VERSION "2027-draft-2026-10-22"

NS_ :

BS_:

BU_: Blackbody1 Blackbody2 Blackbody3 ChassisIMU StrainGauge1 StrainGauge2 StrainGauge3 StrainGauge4 StrainGauge5 StrainGauge6 SuspensionFL SuspensionFR SuspensionRear TelemetryLeader UprightFL UprightFR UprightRear
VAL_TABLE_ EnableDisable 1 "Enabled" 0 "Disabled" ;
VAL_TABLE_ OnOff 1 "On" 0 "Off" ;
VAL_TABLE_ FaultState 1 "Fault" 0 "OK" ;
VAL_TABLE_ WarningState 1 "Warning" 0 "NoWarning" ;
VAL_TABLE_ DeviceStatus 2 "Waiting" 1 "Fault" 0 "OK" ;
VAL_TABLE_ Permission 1 "Allowed" 0 "NotAllowed" ;
VAL_TABLE_ Connection 1 "Connected" 0 "Disconnected" ;
VAL_TABLE_ Pressed 1 "Pressed" 0 "NotPressed" ;
VAL_TABLE_ Validity 1 "Valid" 0 "Invalid" ;
VAL_TABLE_ Watchdog 1 "TimedOut" 0 "Alive" ;
VAL_TABLE_ NormalAdvanced 1 "Advanced" 0 "Normal" ;
VAL_TABLE_ MotorCommandSource 1 "External" 0 "VCU" ;
VAL_TABLE_ Gear 3 "Invalid" 2 "Reverse" 1 "Forward" 0 "Neutral" ;
VAL_TABLE_ BPSFaultSummary 5 "SMBFault" 4 "PrechargeFault" 3 "ContactorRelayFault" 2 "EmergencyStop" 1 "SetpointFault" 0 "OK" ;
VAL_TABLE_ VCUState 7 "VehicleNotReady" 6 "Disabled" 5 "CruiseControl" 4 "Regen" 3 "ReverseDrive" 2 "NeutralDrive" 1 "ForwardDrive" 0 "Init" ;
VAL_TABLE_ ChargeState 2 "Charging" 1 "Standby" 0 "Disabled" ;
VAL_TABLE_ EVSEState 5 "F_EVSEFault" 4 "E_Fault" 3 "D_VentilationRequired" 2 "C_ChargingReady" 1 "B_Connected" 0 "A_Disconnected" ;
VAL_TABLE_ GPSAntennaState 3 "Unknown" 2 "ShortCircuit" 1 "OpenCircuit" 0 "OK" ;
VAL_TABLE_ GPSFix 2 "Fix3D" 1 "Fix2D" 0 "NoFix" ;
VAL_TABLE_ CellularTechnology 4 "Other" 3 "NB_IoT" 2 "LTE_M" 1 "LTE" 0 "None" ;
VAL_TABLE_ TPEEControlMode 2 "ConstantInputVoltage" 1 "PerturbAndObserve" 0 "Disabled" ;
VAL_TABLE_ TPEEOperatingMode 7 "Fault" 6 "MinimumInputVoltage" 5 "TemperatureDerating" 4 "ConstantOutputCurrent" 3 "ConstantOutputVoltage" 2 "MinimumInputCurrent" 1 "ConstantInputCurrent" 0 "ConstantInputVoltage" ;
VAL_TABLE_ TPEEFault 8 "Fault" 7 "PhaseOverCurrent" 6 "InputUnderCurrent" 5 "InputOverCurrent" 4 "OutputOverCurrent" 3 "OutputOverVoltage" 2 "InputOverVoltage" 1 "ConfigurationError" 0 "OK" ;
VAL_TABLE_ LWSCalibration 1 "Calibrated" 0 "NotCalibrated" ;
VAL_TABLE_ LWSTrim 1 "Trimmed" 0 "NotTrimmed" ;
VAL_TABLE_ LWSCommand 5 "ResetCalibration" 3 "SetAngleZero" ;
VAL_TABLE_ ElconControl 1 "Disable" 0 "Charge" ;
VAL_TABLE_ ElconMuxPage 5 "Page5" 4 "Page4" 3 "Page3" 2 "Page2" 1 "Page1" ;

BO_ 1568 TelemetryLeaderTimestampSync: 0 TelemetryLeader

BO_ 1569 TelemetryLeaderStatus: 24 TelemetryLeader
 SG_ GPSLongitude : 0|32@1- (1e-06,0) [-180|180] "deg" Vector__XXX
 SG_ GPSLatitude : 32|32@1- (1e-06,0) [-90|90] "deg" Vector__XXX
 SG_ GPSSpeed : 64|16@1+ (0.01,0) [0.0|655.35] "m/s" Vector__XXX
 SG_ GPSHeading : 80|16@1+ (0.01,0) [0|359.99] "deg" Vector__XXX
 SG_ GPSAltitude : 96|16@1- (0.1,0) [-3276.8|3276.7] "m" Vector__XXX
 SG_ GPSAntennaState : 112|2@1+ (1,0) [0.0|3.0] "" Vector__XXX
 SG_ GPSFix : 114|2@1+ (1,0) [0.0|3.0] "" Vector__XXX
 SG_ SatellitesInUse : 116|8@1+ (1,0) [0.0|255.0] "" Vector__XXX
 SG_ CellularConnected : 124|1@1+ (1,0) [0.0|1.0] "" Vector__XXX
 SG_ RSSI : 128|8@1- (1,0) [-128.0|127.0] "dBm" Vector__XXX
 SG_ RSRP : 136|8@1- (1,0) [-128.0|127.0] "dBm" Vector__XXX
 SG_ RSRQ : 144|8@1- (0.5,0) [-64.0|63.5] "dB" Vector__XXX
 SG_ SINR : 152|8@1- (0.5,0) [-64.0|63.5] "dB" Vector__XXX
 SG_ CellularTechnology : 160|3@1+ (1,0) [0.0|7.0] "" Vector__XXX
 SG_ Roaming : 163|1@1+ (1,0) [0.0|1.0] "" Vector__XXX
 SG_ InternetConnected : 164|1@1+ (1,0) [0.0|1.0] "" Vector__XXX

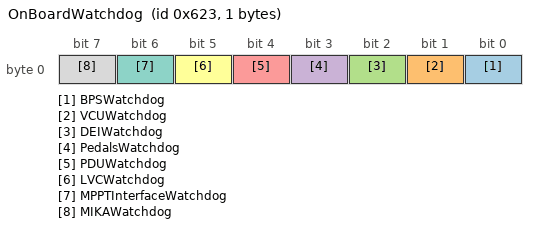
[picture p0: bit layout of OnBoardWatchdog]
BO_ 1571 OnBoardWatchdog: 1 TelemetryLeader
 SG_ BPSWatchdog : 0|1@1+ (1,0) [0.0|1.0] "" Vector__XXX
 SG_ VCUWatchdog : 1|1@1+ (1,0) [0.0|1.0] "" Vector__XXX
 SG_ DEIWatchdog : 2|1@1+ (1,0) [0.0|1.0] "" Vector__XXX
 SG_ PedalsWatchdog : 3|1@1+ (1,0) [0.0|1.0] "" Vector__XXX
 SG_ PDUWatchdog : 4|1@1+ (1,0) [0.0|1.0] "" Vector__XXX
 SG_ LVCWatchdog : 5|1@1+ (1,0) [0.0|1.0] "" Vector__XXX
 SG_ MPPTInterfaceWatchdog : 6|1@1+ (1,0) [0.0|1.0] "" Vector__XXX
 SG_ MIKAWatchdog : 7|1@1+ (1,0) [0.0|1.0] "" Vector__XXX

BO_ 1584 ChassisIMUData: 0 ChassisIMU

BO_ 1585 UprightFRData: 0 UprightFR

BO_ 1586 UprightFLData: 0 UprightFL

BO_ 1587 UprightRearData: 0 UprightRear

BO_ 1588 SuspensionFRData: 0 SuspensionFR

BO_ 1589 SuspensionFLData: 0 SuspensionFL

BO_ 1590 SuspensionRearData: 0 SuspensionRear

BO_ 1591 Blackbody1Data: 0 Blackbody1

BO_ 1592 Blackbody2Data: 0 Blackbody2

BO_ 1593 Blackbody3Data: 0 Blackbody3

BO_ 1594 StrainGauge1Data: 0 StrainGauge1

BO_ 1595 StrainGauge2Data: 0 StrainGauge2

BO_ 1596 StrainGauge3Data: 0 StrainGauge3

BO_ 1597 StrainGauge4Data: 0 StrainGauge4

BO_ 1598 StrainGauge5Data: 0 StrainGauge5

BO_ 1599 StrainGauge6Data: 0 StrainGauge6

CM_ BO_ 1568 "PLACEHOLDER: signals and payload length are not defined; zero DLC is a drafting marker, not an approved transmit layout. ";
CM_ BO_ 1569 "2027 team-defined layout; physical values use the shared scaling conventions.";
CM_ SG_ 1569 InternetConnected "InternetConnected";
CM_ SG_ 1569 Roaming "Roaming";
CM_ SG_ 1569 CellularTechnology "CellularTechnology";
CM_ SG_ 1569 SINR "SINR";
CM_ SG_ 1569 RSRQ "RSRQ";
CM_ SG_ 1569 RSRP "RSRP";
CM_ SG_ 1569 RSSI "RSSI";
CM_ SG_ 1569 CellularConnected "CellularConnected";
CM_ SG_ 1569 SatellitesInUse "SatellitesInUse";
CM_ SG_ 1569 GPSFix "GPSFix";
CM_ SG_ 1569 GPSAntennaState "GPSAntennaState";
CM_ SG_ 1569 GPSAltitude "GPSAltitude";
CM_ SG_ 1569 GPSHeading "GPSHeading";
CM_ SG_ 1569 GPSSpeed "GPSSpeed";
CM_ SG_ 1569 GPSLatitude "GPSLatitude";
CM_ SG_ 1569 GPSLongitude "Longitude range corrected from swapped draft coordinates.";
CM_ BO_ 1571 "One bit per monitored device: 0=alive, 1=timed out. Watchdog timeouts are configured by firmware, not encoded here.";
CM_ SG_ 1571 MIKAWatchdog "MIKAWatchdog";
CM_ SG_ 1571 MPPTInterfaceWatchdog "MPPTInterfaceWatchdog";
CM_ SG_ 1571 LVCWatchdog "LVCWatchdog";
CM_ SG_ 1571 PDUWatchdog "PDUWatchdog";
CM_ SG_ 1571 PedalsWatchdog "PedalsWatchdog";
CM_ SG_ 1571 DEIWatchdog "DEIWatchdog";
CM_ SG_ 1571 VCUWatchdog "VCUWatchdog";
CM_ SG_ 1571 BPSWatchdog "BPSWatchdog";
CM_ BO_ 1584 "PLACEHOLDER: signals and payload length are not defined; zero DLC is a drafting marker, not an approved transmit layout. ";
CM_ BO_ 1585 "PLACEHOLDER: signals and payload length are not defined; zero DLC is a drafting marker, not an approved transmit layout. ";
CM_ BO_ 1586 "PLACEHOLDER: signals and payload length are not defined; zero DLC is a drafting marker, not an approved transmit layout. ";
CM_ BO_ 1587 "PLACEHOLDER: signals and payload length are not defined; zero DLC is a drafting marker, not an approved transmit layout. ";
CM_ BO_ 1588 "PLACEHOLDER: signals and payload length are not defined; zero DLC is a drafting marker, not an approved transmit layout. ";
CM_ BO_ 1589 "PLACEHOLDER: signals and payload length are not defined; zero DLC is a drafting marker, not an approved transmit layout. ";
CM_ BO_ 1590 "PLACEHOLDER: signals and payload length are not defined; zero DLC is a drafting marker, not an approved transmit layout. ";
CM_ BO_ 1591 "PLACEHOLDER: signals and payload length are not defined; zero DLC is a drafting marker, not an approved transmit layout. ";
CM_ BO_ 1592 "PLACEHOLDER: signals and payload length are not defined; zero DLC is a drafting marker, not an approved transmit layout. ";
CM_ BO_ 1593 "PLACEHOLDER: signals and payload length are not defined; zero DLC is a drafting marker, not an approved transmit layout. ";
CM_ BO_ 1594 "PLACEHOLDER: signals and payload length are not defined; zero DLC is a drafting marker, not an approved transmit layout. ";
CM_ BO_ 1595 "PLACEHOLDER: signals and payload length are not defined; zero DLC is a drafting marker, not an approved transmit layout. ";
CM_ BO_ 1596 "PLACEHOLDER: signals and payload length are not defined; zero DLC is a drafting marker, not an approved transmit layout. ";
CM_ BO_ 1597 "PLACEHOLDER: signals and payload length are not defined; zero DLC is a drafting marker, not an approved transmit layout. ";
CM_ BO_ 1598 "PLACEHOLDER: signals and payload length are not defined; zero DLC is a drafting marker, not an approved transmit layout. ";
CM_ BO_ 1599 "PLACEHOLDER: signals and payload length are not defined; zero DLC is a drafting marker, not an approved transmit layout. ";
BA_DEF_ SG_  "ValueTable" STRING ;
BA_DEF_ BO_  "LayoutPending" INT 0 1;
BA_DEF_ BO_  "ProtocolSource" STRING ;
BA_DEF_  "BusType" STRING ;
BA_DEF_  "DBName" STRING ;
BA_DEF_ BO_  "VFrameFormat" ENUM  "StandardCAN","ExtendedCAN","reserved","J1939PG","reserved","reserved","reserved","reserved","reserved","reserved","reserved","reserved","reserved","reserved","StandardCAN_FD","ExtendedCAN_FD";
BA_DEF_ BO_  "CANFD_BRS" ENUM  "0","1";
BA_DEF_DEF_  "ValueTable" "";
BA_DEF_DEF_  "LayoutPending" 0;
BA_DEF_DEF_  "ProtocolSource" "";
BA_DEF_DEF_  "BusType" "CAN";
BA_DEF_DEF_  "DBName" "";
BA_DEF_DEF_  "VFrameFormat" "StandardCAN";
BA_DEF_DEF_  "CANFD_BRS" "1";
BA_ "BusType" "CAN FD";
BA_ "DBName" "TelemetryCAN";
BA_ "LayoutPending" BO_ 1568 1;
BA_ "ProtocolSource" BO_ 1568 "2027 allocation draft";
BA_ "VFrameFormat" BO_ 1568 14;
BA_ "ProtocolSource" BO_ 1569 "2027 allocation draft";
BA_ "VFrameFormat" BO_ 1569 14;
BA_ "ValueTable" SG_ 1569 InternetConnected "Connection";
BA_ "ValueTable" SG_ 1569 Roaming "OnOff";
BA_ "ValueTable" SG_ 1569 CellularTechnology "CellularTechnology";
BA_ "ValueTable" SG_ 1569 CellularConnected "Connection";
BA_ "ValueTable" SG_ 1569 GPSFix "GPSFix";
BA_ "ValueTable" SG_ 1569 GPSAntennaState "GPSAntennaState";
BA_ "ProtocolSource" BO_ 1571 "2027 allocation draft";
BA_ "VFrameFormat" BO_ 1571 14;
BA_ "ValueTable" SG_ 1571 MIKAWatchdog "Watchdog";
BA_ "ValueTable" SG_ 1571 MPPTInterfaceWatchdog "Watchdog";
BA_ "ValueTable" SG_ 1571 LVCWatchdog "Watchdog";
BA_ "ValueTable" SG_ 1571 PDUWatchdog "Watchdog";
BA_ "ValueTable" SG_ 1571 PedalsWatchdog "Watchdog";
BA_ "ValueTable" SG_ 1571 DEIWatchdog "Watchdog";
BA_ "ValueTable" SG_ 1571 VCUWatchdog "Watchdog";
BA_ "ValueTable" SG_ 1571 BPSWatchdog "Watchdog";
BA_ "LayoutPending" BO_ 1584 1;
BA_ "ProtocolSource" BO_ 1584 "2027 allocation draft";
BA_ "VFrameFormat" BO_ 1584 14;
BA_ "LayoutPending" BO_ 1585 1;
BA_ "ProtocolSource" BO_ 1585 "2027 allocation draft";
BA_ "VFrameFormat" BO_ 1585 14;
BA_ "LayoutPending" BO_ 1586 1;
BA_ "ProtocolSource" BO_ 1586 "2027 allocation draft";
BA_ "VFrameFormat" BO_ 1586 14;
BA_ "LayoutPending" BO_ 1587 1;
BA_ "ProtocolSource" BO_ 1587 "2027 allocation draft";
BA_ "VFrameFormat" BO_ 1587 14;
BA_ "LayoutPending" BO_ 1588 1;
BA_ "ProtocolSource" BO_ 1588 "2027 allocation draft";
BA_ "VFrameFormat" BO_ 1588 14;
BA_ "LayoutPending" BO_ 1589 1;
BA_ "ProtocolSource" BO_ 1589 "2027 allocation draft";
BA_ "VFrameFormat" BO_ 1589 14;
BA_ "LayoutPending" BO_ 1590 1;
BA_ "ProtocolSource" BO_ 1590 "2027 allocation draft";
BA_ "VFrameFormat" BO_ 1590 14;
BA_ "LayoutPending" BO_ 1591 1;
BA_ "ProtocolSource" BO_ 1591 "2027 allocation draft";
BA_ "VFrameFormat" BO_ 1591 14;
BA_ "LayoutPending" BO_ 1592 1;
BA_ "ProtocolSource" BO_ 1592 "2027 allocation draft";
BA_ "VFrameFormat" BO_ 1592 14;
BA_ "LayoutPending" BO_ 1593 1;
BA_ "ProtocolSource" BO_ 1593 "2027 allocation draft";
BA_ "VFrameFormat" BO_ 1593 14;
BA_ "LayoutPending" BO_ 1594 1;
BA_ "ProtocolSource" BO_ 1594 "2027 allocation draft";
BA_ "VFrameFormat" BO_ 1594 14;
BA_ "LayoutPending" BO_ 1595 1;
BA_ "ProtocolSource" BO_ 1595 "2027 allocation draft";
BA_ "VFrameFormat" BO_ 1595 14;
BA_ "LayoutPending" BO_ 1596 1;
BA_ "ProtocolSource" BO_ 1596 "2027 allocation draft";
BA_ "VFrameFormat" BO_ 1596 14;
BA_ "LayoutPending" BO_ 1597 1;
BA_ "ProtocolSource" BO_ 1597 "2027 allocation draft";
BA_ "VFrameFormat" BO_ 1597 14;
BA_ "LayoutPending" BO_ 1598 1;
BA_ "ProtocolSource" BO_ 1598 "2027 allocation draft";
BA_ "VFrameFormat" BO_ 1598 14;
BA_ "LayoutPending" BO_ 1599 1;
BA_ "ProtocolSource" BO_ 1599 "2027 allocation draft";
BA_ "VFrameFormat" BO_ 1599 14;
VAL_ 1569 InternetConnected 0 "Disconnected" 1 "Connected" ;
VAL_ 1569 Roaming 0 "Off" 1 "On" ;
VAL_ 1569 CellularTechnology 0 "None" 1 "LTE" 2 "LTE_M" 3 "NB_IoT" 4 "Other" ;
VAL_ 1569 CellularConnected 0 "Disconnected" 1 "Connected" ;
VAL_ 1569 GPSFix 0 "NoFix" 1 "Fix2D" 2 "Fix3D" ;
VAL_ 1569 GPSAntennaState 0 "OK" 1 "OpenCircuit" 2 "ShortCircuit" 3 "Unknown" ;
VAL_ 1571 MIKAWatchdog 0 "Alive" 1 "TimedOut" ;
VAL_ 1571 MPPTInterfaceWatchdog 0 "Alive" 1 "TimedOut" ;
VAL_ 1571 LVCWatchdog 0 "Alive" 1 "TimedOut" ;
VAL_ 1571 PDUWatchdog 0 "Alive" 1 "TimedOut" ;
VAL_ 1571 PedalsWatchdog 0 "Alive" 1 "TimedOut" ;
VAL_ 1571 DEIWatchdog 0 "Alive" 1 "TimedOut" ;
VAL_ 1571 VCUWatchdog 0 "Alive" 1 "TimedOut" ;
VAL_ 1571 BPSWatchdog 0 "Alive" 1 "TimedOut" ;
